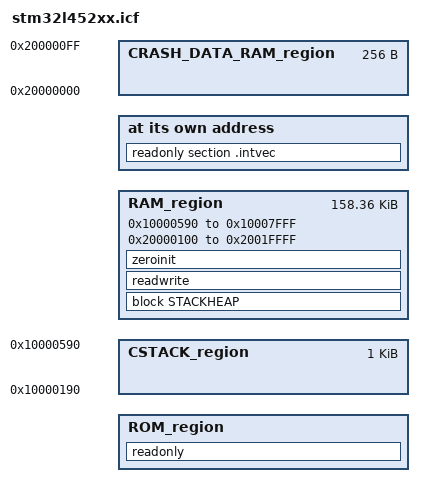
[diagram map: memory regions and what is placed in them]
if (!isdefinedsymbol(MBED_APP_START)) { define symbol MBED_APP_START = 0x08000000; }
if (!isdefinedsymbol(MBED_APP_SIZE)) { define symbol MBED_APP_SIZE = 0x80000; }

/* [ROM = 512kb = 0x80000] */
define symbol __intvec_start__     = MBED_APP_START;
define symbol __region_ROM_start__ = MBED_APP_START;
define symbol __region_ROM_end__   = MBED_APP_START + MBED_APP_SIZE - 1;

/* [RAM = 128kb + 32kb = 0x28000] */
/* Vector table dynamic copy: Total: 99 vectors * 4 = 396 bytes (0x18C) to be reserved in RAM */
define symbol __NVIC_start__          = 0x10000000;
define symbol __NVIC_end__            = 0x1000018F; /* Add 4 more bytes to be aligned on 8 bytes */
/* SRAM2 is also aliased to be between 0x2002000 and 0x20027FFF, but sticking with previous convention. */
define symbol __region_CSTACK_start__  = 0x10000190;
define symbol __region_CSTACK_end__    = __region_CSTACK_start__ + MBED_BOOT_STACK_SIZE;
define symbol __region_SRAM2_start__  = __region_CSTACK_end__;
define symbol __region_SRAM2_end__    = 0x10007FFF;
define symbol __region_CRASH_DATA_RAM_start__  = 0x20000000;
define symbol __region_CRASH_DATA_RAM_end__  = 0x200000FF;
define symbol __region_SRAM1_start__  = 0x20000100;
define symbol __region_SRAM1_end__    = 0x2001FFFF;

/* Memory regions */
define memory mem with size = 4G;
define region ROM_region = mem:[from __region_ROM_start__ to __region_ROM_end__];
define region CSTACK_region = mem:[from __region_CSTACK_start__ to __region_CSTACK_end__];
define region CRASH_DATA_RAM_region = mem:[from __region_CRASH_DATA_RAM_start__ to __region_CRASH_DATA_RAM_end__];
define region RAM_region = mem:[from __region_SRAM2_start__ to __region_SRAM2_end__]
                          | mem:[from __region_SRAM1_start__ to __region_SRAM1_end__];

/* Define Crash Data Symbols */
define exported symbol __CRASH_DATA_RAM_START__ = __region_CRASH_DATA_RAM_start__;
define exported symbol __CRASH_DATA_RAM_END__ = __region_CRASH_DATA_RAM_end__;

if (!isdefinedsymbol(MBED_BOOT_STACK_SIZE)) {
    define symbol MBED_BOOT_STACK_SIZE = 0x400;
}

define symbol __size_cstack__ = MBED_BOOT_STACK_SIZE;
define symbol __size_heap__   = 0x10000;
define block CSTACK    with alignment = 8, size = __size_cstack__   { };
define block HEAP      with expanding size, alignment = 8, minimum size = __size_heap__     { };
define block STACKHEAP with fixed order { block HEAP, block CSTACK };

initialize by copy with packing = zeros { readwrite };
do not initialize  { section .noinit };

place at address mem:__intvec_start__ { readonly section .intvec };

place in ROM_region   { readonly };
place in RAM_region   { block STACKHEAP, readwrite, zeroinit };
